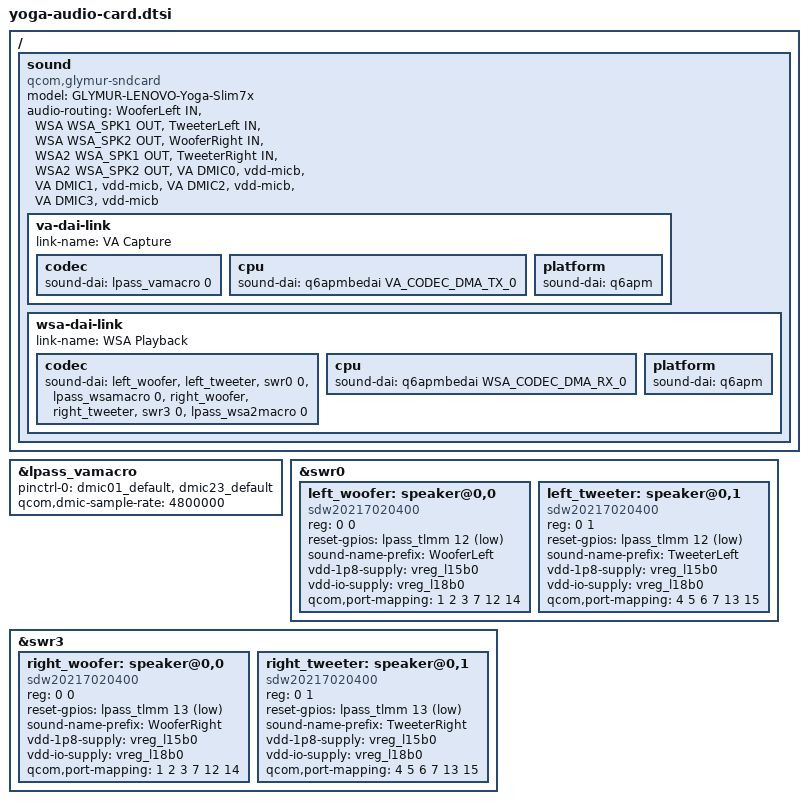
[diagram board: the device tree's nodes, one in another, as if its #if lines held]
// SPDX-License-Identifier: BSD-3-Clause
/*
 * FRENTE AUDIO, etapa 3: placa de som (4x WSA8845 em swr0/swr3 + VA/DMIC).
 * Acrescimo ao yoga-audio.dtsi; incluir DEPOIS dele (precisa do ADSP okay e
 * de "qcom,mahua" na raiz para o pd-mapper).
 *
 * REF  = arch/arm64/boot/dts/qcom/glymur-lenovo-yoga-slim7x.dts (mesmo chassi)
 * CRD  = arch/arm64/boot/dts/qcom/glymur-crd.dtsi
 * DSDT = local/iso-build/acpi/acpi-registry-0000.dsl
 * INF  = coleta Windows, qcaucd_ext_crd8480.inf (casa ADCM\...SUBSYS_17AA3803,
 *        o id desta maquina em logs/pnp-devices.txt, e SUBSYS_CRD08480)
 * LOG  = local/physical-2026-11-16/gwnx1/08-gpio.txt (ADSP rodando)
 *
 * BOOT NEUTRO: nada aqui da probe sem carga manual. Os nos novos (swr0, swr3,
 * sound) so casam com soundwire_qcom e snd_soc_x1e80100, ambos ja na
 * modprobe.blacklist do slot; os alto-falantes so viram dispositivo depois que
 * o soundwire_qcom sobe. Nenhum regulador novo, nenhuma propriedade de
 * regulador alterada, nenhum pino do TLMM.
 * Bloquear (ja estao todos na cmdline do slot current):
 *   qcom_pd_mapper,apr,fastrpc,snd_q6apm,q6prm,q6prm_clocks,q6apm_dai,
 *   q6apm_lpass_dais,snd_soc_lpass_wsa_macro,snd_soc_lpass_va_macro,
 *   soundwire_qcom,snd_soc_wsa884x,snd_soc_x1e80100
 *
 * UNICA SAIDA DE GPIO: SD_N dos amplificadores, pinos 12 e 13 do pinctrl
 * LPASS (lpass_tlmm), ativos em nivel baixo. Evidencia:
 *  - numero: DSDT:72391 e 72397, \_SB.ADSP.ADCM.AUCD com GpioIo 0xCC e 0xCD
 *    (TLMM 204/205). pinctrl-glymur.c:1645 em diante: os pinos "egpio" do
 *    TLMM comecam em 192 e o LPI tem 23 pinos, logo 204/205 = LPI 12/13.
 *    No mesmo _CRS (DSDT:72401,72405), Interrupt 0xCA e 0xCB = GIC SPI 170 e 171 = swr0 e swr3
 *    (glymur.dtsi:4556 e 4600).
 *  - funcao e polaridade: REF:692,704,720,732 e CRD:745,757,773,785
 *    (GPIO_ACTIVE_LOW); INF: AUCD\GPIO\1 e \2 com INITIALVALUE 0 (driver
 *    Windows comeca com o pino em 0 = amplificador desligado).
 *  - estado lido: LOG:388-389 "gpio12 : in low func0 2mA pull down" e
 *    "gpio13 : in low ..." = amplificadores em shutdown. O driver pede o
 *    reset ja afirmado (nivel baixo, igual ao lido) e so sobe o pino no
 *    probe do snd_soc_wsa884x (carga manual).
 * Os pinos de SoundWire (LPI 10/11 e 15/16) ja vem de glymur.dtsi.
 *
 * Supplies dos amplificadores: vreg_l15b0 e vreg_l18b0, ambos
 * regulator-always-on em glymur-cob.dtsi:53-69 (nao desligam no remove).
 *
 * MICROFONES: a placa registra o link "VA Capture", mas os pinos de DMIC
 * (LPI 6-9, clock de saida) nao aparecem no DSDT e ficam FORA por padrao;
 * sem eles a captura grava silencio. -DYOGA_AUDIO_DMIC_PINS aplica o
 * pinctrl da REF:495-497 (hipotese: mesma fiacao da variante Elite).
 *
 * model = REF:266. Topologia pedida pelo kernel (topology.c:1443):
 * qcom/glymur/GLYMUR-LENOVO-Yoga-Slim7x-tplg.bin (instalar descomprimida;
 * ver install/audio/).
 */

/ {
	/* REF:264-309 */
	sound {
		compatible = "qcom,glymur-sndcard";
		model = "GLYMUR-LENOVO-Yoga-Slim7x";
		audio-routing = "WooferLeft IN", "WSA WSA_SPK1 OUT",
				"TweeterLeft IN", "WSA WSA_SPK2 OUT",
				"WooferRight IN", "WSA2 WSA_SPK1 OUT",
				"TweeterRight IN", "WSA2 WSA_SPK2 OUT",
				"VA DMIC0", "vdd-micb",
				"VA DMIC1", "vdd-micb",
				"VA DMIC2", "vdd-micb",
				"VA DMIC3", "vdd-micb";

		va-dai-link {
			link-name = "VA Capture";

			codec {
				sound-dai = <&lpass_vamacro 0>;
			};

			cpu {
				sound-dai = <&q6apmbedai VA_CODEC_DMA_TX_0>;
			};

			platform {
				sound-dai = <&q6apm>;
			};
		};

		wsa-dai-link {
			link-name = "WSA Playback";

			codec {
				sound-dai = <&left_woofer>, <&left_tweeter>,
					    <&swr0 0>, <&lpass_wsamacro 0>,
					    <&right_woofer>, <&right_tweeter>,
					    <&swr3 0>, <&lpass_wsa2macro 0>;
			};

			cpu {
				sound-dai = <&q6apmbedai WSA_CODEC_DMA_RX_0>;
			};

			platform {
				sound-dai = <&q6apm>;
			};
		};
	};
};

/* REF:495-499 */
&lpass_vamacro {
#ifdef YOGA_AUDIO_DMIC_PINS
	pinctrl-0 = <&dmic01_default>, <&dmic23_default>;
	pinctrl-names = "default";
#endif
	qcom,dmic-sample-rate = <4800000>;
};

/* REF:685-711 */
&swr0 {
	status = "okay";

	/* WSA8845, Left Woofer */
	left_woofer: speaker@0,0 {
		compatible = "sdw20217020400";
		reg = <0 0>;
		reset-gpios = <&lpass_tlmm 12 GPIO_ACTIVE_LOW>;
		#sound-dai-cells = <0>;
		sound-name-prefix = "WooferLeft";
		vdd-1p8-supply = <&vreg_l15b0>;
		vdd-io-supply = <&vreg_l18b0>;
		qcom,port-mapping = <1 2 3 7 12 14>;
	};

	/* WSA8845, Left Tweeter */
	left_tweeter: speaker@0,1 {
		compatible = "sdw20217020400";
		reg = <0 1>;
		reset-gpios = <&lpass_tlmm 12 GPIO_ACTIVE_LOW>;
		#sound-dai-cells = <0>;
		sound-name-prefix = "TweeterLeft";
		vdd-1p8-supply = <&vreg_l15b0>;
		vdd-io-supply = <&vreg_l18b0>;
		qcom,port-mapping = <4 5 6 7 13 15>;
	};
};

/* REF:713-739 */
&swr3 {
	status = "okay";

	/* WSA8845, Right Woofer */
	right_woofer: speaker@0,0 {
		compatible = "sdw20217020400";
		reg = <0 0>;
		reset-gpios = <&lpass_tlmm 13 GPIO_ACTIVE_LOW>;
		#sound-dai-cells = <0>;
		sound-name-prefix = "WooferRight";
		vdd-1p8-supply = <&vreg_l15b0>;
		vdd-io-supply = <&vreg_l18b0>;
		qcom,port-mapping = <1 2 3 7 12 14>;
	};

	/* WSA8845, Right Tweeter */
	right_tweeter: speaker@0,1 {
		compatible = "sdw20217020400";
		reg = <0 1>;
		reset-gpios = <&lpass_tlmm 13 GPIO_ACTIVE_LOW>;
		#sound-dai-cells = <0>;
		sound-name-prefix = "TweeterRight";
		vdd-1p8-supply = <&vreg_l15b0>;
		vdd-io-supply = <&vreg_l18b0>;
		qcom,port-mapping = <4 5 6 7 13 15>;
	};
};
